# ATxmega16E5 device description
Architecture: AVR8_XMEGA; Family: AVR XMEGA
Registers are 8-bit, access not given, no defined reset value unless marked. A register's access mark holds for its fields unless they carry their own. Offsets are from the block's base; [hi:lo] are bit positions; lines under a group give offsets from that group; {n}, {i} and the like mark numbered series; 'fields as' and 'values as' point back to an identical list.

## TWI — Two-Wire Interface
Instances: TWIC 0x480
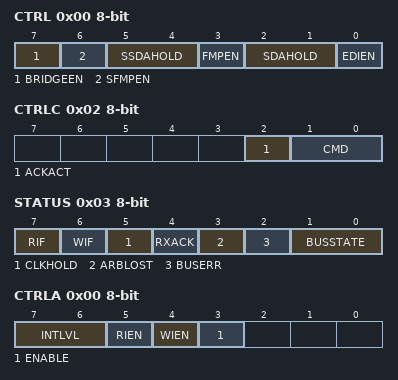
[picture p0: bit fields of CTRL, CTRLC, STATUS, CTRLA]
0x00 CTRL — TWI Common Control Register
  [7] BRIDGEEN — Bridge Enable
  [6] SFMPEN — Slave Fast Mode Plus Enable
  [5:4] SSDAHOLD — Slave SDA Hold Time Enable
    0=OFF (SDA Hold Time off); 1=50NS (SDA Hold Time 50 ns); 2=300NS (SDA Hold Time 300 ns); 3=400NS (SDA Hold Time 400 ns)
  [3] FMPEN — FMPLUS Enable
  [2:1] SDAHOLD — SDA Hold Time Enable
    values as SSDAHOLD
  [0] EDIEN — External Driver Interface Enable
0x01 MASTER group — TWI master module
  0x00 CTRLA — Control Register A
    [7:6] INTLVL — Interrupt Level
      0=OFF (Interrupt Disabled); 1=LO (Low Level); 2=MED (Medium Level); 3=HI (High Level)
    [5] RIEN — Read Interrupt Enable
    [4] WIEN — Write Interrupt Enable
    [3] ENABLE — Enable TWI Master
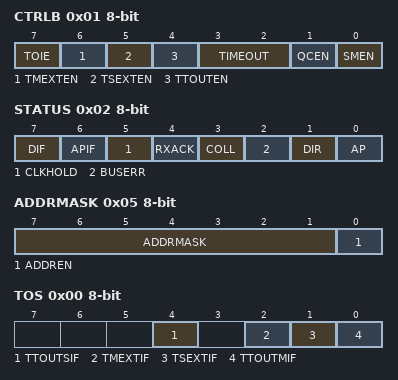
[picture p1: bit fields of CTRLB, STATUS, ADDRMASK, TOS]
  0x01 CTRLB — Control Register B
    [7] TOIE — Timeout Interrupt Enable
    [6] TMEXTEN — Master Extend Timeout Enable
    [5] TSEXTEN — Slave Extend Timeout Enable
    [4] TTOUTEN — Ttimeout Enable
    [3:2] TIMEOUT — Inactive Bus Timeout
      0=DISABLED (Bus Timeout Disabled); 1=50US (50 Microseconds); 2=100US (100 Microseconds); 3=200US (200 Microseconds)
    [1] QCEN — Quick Command Enable
    [0] SMEN — Smart Mode Enable
  0x02 CTRLC — Control Register C
    [2] ACKACT — Acknowledge Action
    [1:0] CMD — Command
      0=NOACT (No Action); 1=REPSTART (Issue Repeated Start Condition); 2=RECVTRANS (Receive or Transmit Data); 3=STOP (Issue Stop Condition)
  0x03 STATUS
    [7] RIF — Read Interrupt Flag
    [6] WIF — Write Interrupt Flag
    [5] CLKHOLD — Clock Hold
    [4] RXACK — Received Acknowledge
    [3] ARBLOST — Arbitration Lost
    [2] BUSERR — Bus Error
    [1:0] BUSSTATE
      0=UNKNOWN (Unknown Bus State); 1=IDLE (Bus is Idle); 2=OWNER (This Module Controls The Bus); 3=BUSY (The Bus is Busy)
  0x04 BAUD — Baurd Rate Control Register
  0x05 ADDR — Address Register
  0x06 DATA
0x08 SLAVE group — TWI slave module
  0x00 CTRLA — Control Register A
    [7:6] INTLVL — Interrupt Level
      values as MASTER.CTRLA.INTLVL
    [5] DIEN — Data Interrupt Enable
    [4] APIEN — Address/Stop Interrupt Enable
    [3] ENABLE — Enable TWI Slave
    [2] PIEN — Stop Interrupt Enable
    [1] PMEN — Promiscuous Mode Enable
    [0] SMEN — Smart Mode Enable
  0x01 CTRLB — Control Register B
    [7] TOIE — Timeout Interrupt Enable
    [4] TTOUTEN — Ttimeout Enable
    [2] ACKACT — Acknowledge Action
    [1:0] CMD — Command
      0=NOACT (No Action); 2=COMPTRANS (Used To Complete a Transaction); 3=RESPONSE (Used in Response to Address/Data Interrupt)
  0x02 STATUS
    [7] DIF — Data Interrupt Flag
    [6] APIF — Address/Stop Interrupt Flag
    [5] CLKHOLD — Clock Hold
    [4] RXACK — Received Acknowledge
    [3] COLL — Collision
    [2] BUSERR — Bus Error
    [1] DIR — Read/Write Direction
    [0] AP — Slave Address or Stop
  0x03 ADDR — Address Register
  0x04 DATA
  0x05 ADDRMASK — Address Mask Register
    [7:1] ADDRMASK — Address Mask
    [0] ADDREN — Address Enable
0x0E TIMEOUT group — TWI SMBUS timeout module
  0x00 TOS — Timeout Status Register
    [4] TTOUTSIF — Slave Ttimeout Interrupt Flag
    [2] TMEXTIF — Master Extend Interrupt Flag
    [1] TSEXTIF — Slave Extend Interrupt Flag
    [0] TTOUTMIF — Master Ttimeout Interrupt Flag
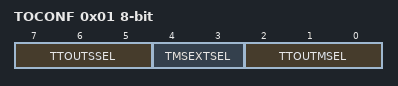
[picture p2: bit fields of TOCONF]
  0x01 TOCONF — Timeout Configuration Register
    [7:5] TTOUTSSEL — Slave Ttimeout Select
      0=25MS (25 Milliseconds); 1=24MS (24 Milliseconds); 2=23MS (23 Milliseconds); 3=22MS (22 Milliseconds); {v}={v+22}MS ({v+22} Milliseconds) (v=4..7)
    [4:3] TMSEXTSEL — Master/Slave Timeout Select
      0=10MS25MS (Tmext 10ms Tsext 25ms); 1=9MS24MS (Tmext 9ms Tsext 24ms); 2=11MS26MS (Tmext 11ms Tsext 26ms); 3=12MS27MS (Tmext 12ms Tsext 27ms)
    [2:0] TTOUTMSEL — Master Ttimeout Select
      values as TTOUTSSEL
